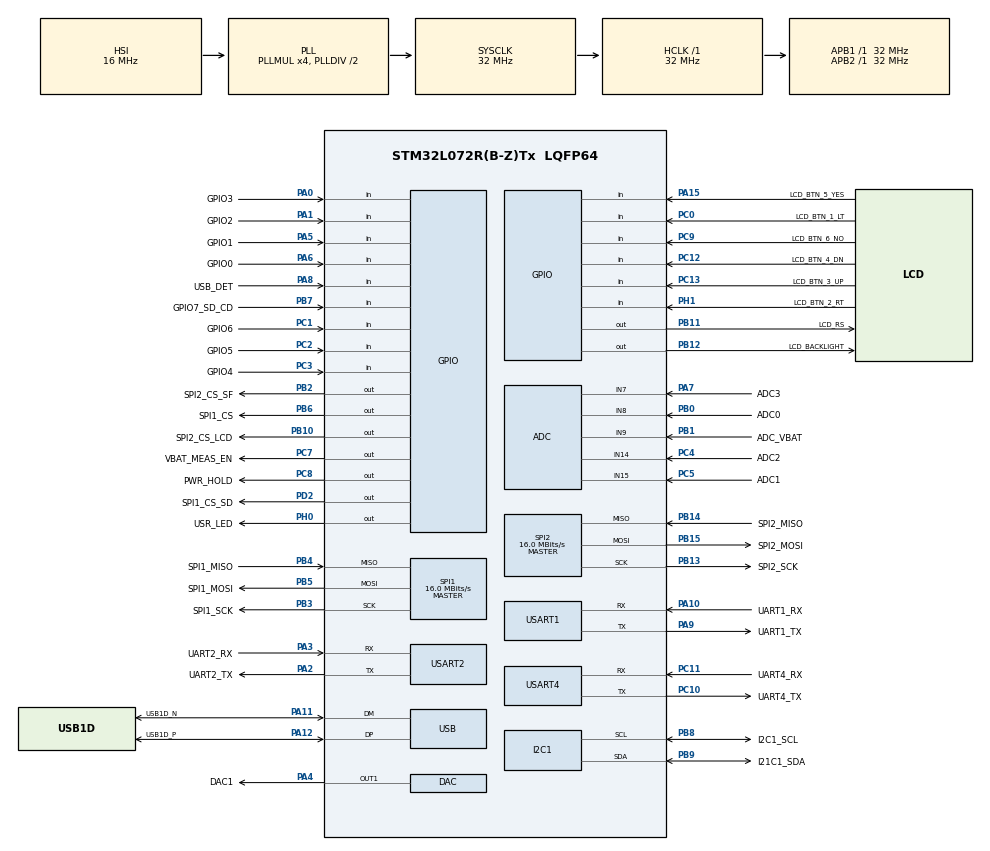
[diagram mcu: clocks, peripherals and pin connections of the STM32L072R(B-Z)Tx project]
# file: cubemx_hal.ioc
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PH0-OSC_IN.Signal=GPIO_Output
SPI1.VirtualType=VM_MASTER
SPI2.VirtualType=VM_MASTER
PA10.GPIO_PuPd=GPIO_PULLUP
PC12.Signal=GPIO_Input
PB14.GPIO_Label=SPI2_MISO
USART1.WordLength=WORDLENGTH_8B
PA14.GPIO_Label=SWCLK
PA3.GPIO_PuPd=GPIO_PULLUP
PC6.GPIO_Label=PWM_BUZZER
VP_RTC_VS_RTC_Activate.Mode=RTC_Enabled
PA6.GPIO_Label=GPIO0
PB6.GPIO_Label=SPI1_CS
PC5.Mode=IN15
PA3.GPIO_Speed=GPIO_SPEED_FREQ_LOW
PB13.Signal=SPI2_SCK
PC15-OSC32_OUT.GPIO_Label=OSC32_OUT
PB3.GPIO_Speed=GPIO_SPEED_FREQ_HIGH
RCC.SYSCLKSource=RCC_SYSCLKSOURCE_PLLCLK
PB11.GPIO_Speed=GPIO_SPEED_FREQ_HIGH
SPI1.Direction=SPI_DIRECTION_2LINES
RCC.APB2TimFreq_Value=32000000
PB6.Signal=GPIO_Output
PC7.Signal=GPIO_Output
PB12.PinState=GPIO_PIN_SET
SPI1.CalculateBaudRate=16.0 MBits/s
PC3.Signal=GPIO_Input
PA1.GPIO_PuPd=GPIO_PULLDOWN
PB2.Signal=GPIO_Output
PB3.Mode=Full_Duplex_Master
PC1.GPIO_PuPd=GPIO_PULLDOWN
RCC.RTCClockSelection=RCC_RTCCLKSOURCE_LSE
PB12.GPIO_Label=LCD_BACKLIGHT
PC4.GPIO_Label=ADC2
RCC.RTCClockSelectionVirtual=RCC_RTCCLKSOURCE_LSE
PB14.Mode=Full_Duplex_Master
PA5.GPIO_PuPd=GPIO_PULLDOWN
PB1.GPIO_Label=ADC_VBAT
SPI2.CalculateBaudRate=16.0 MBits/s
PC11.GPIO_Speed=GPIO_SPEED_FREQ_LOW
PA8.Signal=GPIO_Input
PA0.Signal=GPIO_Input
Mcu.Package=LQFP64
PB9.Signal=I2C1_SDA
PB1.Signal=ADC_IN9
PB14.GPIO_PuPd=GPIO_PULLDOWN
SPI2.Mode=SPI_MODE_MASTER
PA10.Signal=USART1_RX
VP_RTC_VS_RTC_Calendar.Mode=RTC_Calendar
PC11.Mode=Asynchronous
PB8.GPIO_PuPdOD=GPIO_PULLUP
PB5.GPIO_Speed=GPIO_SPEED_FREQ_HIGH
RCC.APB1TimFreq_Value=32000000
PB13.Mode=Full_Duplex_Master
PC12.GPIO_PuPd=GPIO_PULLUP
PA4.GPIO_Label=DAC1
PC4.Mode=IN14
RCC.HSI48_VALUE=48000000
PB7.GPIO_PuPd=GPIO_PULLUP
PA9.GPIO_Label=UART1_TX
PC13.Signal=GPIO_Input
PC6.Signal=S_TIM3_CH1
PC2.Signal=GPIO_Input
PB11.GPIO_Label=LCD_RS
PA11.GPIO_Label=USB1D_N
PC0.Signal=GPIO_Input
PC14-OSC32_IN.Signal=RCC_OSC32_IN
PA3.Mode=Asynchronous
RCC.HSI16_VALUE=16000000
PB8.GPIO_Label=I2C1_SCL
PA8.GPIO_Label=USB_DET
PB14.GPIO_Speed=GPIO_SPEED_FREQ_HIGH
USB_DEVICE.PRODUCT_STRING_CDC_FS=Hero Board
PA9.Signal=USART1_TX
I2C1.Timing=0x00707CBB
PB13.GPIO_Speed=GPIO_SPEED_FREQ_HIGH
PB4.GPIO_PuPd=GPIO_PULLUP
PH1-OSC_OUT.GPIO_PuPd=GPIO_PULLUP
PB10.Signal=GPIO_Output
PB14.Signal=SPI2_MISO
PA5.Signal=GPIO_Input
USART4.VirtualMode-Asynchronous=VM_ASYNC
PB4.GPIO_Label=SPI1_MISO
PB15.GPIO_Label=SPI2_MOSI
SPI1.Mode=SPI_MODE_MASTER
PA1.GPIO_Label=GPIO2
PC9.GPIO_PuPd=GPIO_PULLUP
PH1-OSC_OUT.GPIO_Label=LCD_BTN_2_RT
PA13.Mode=Serial_Wire
PC7.GPIO_Label=VBAT_MEAS_EN
PA4.Signal=COMP_DAC1_group
PB5.Signal=SPI1_MOSI
PA5.GPIO_Label=GPIO1
PC12.GPIO_Label=LCD_BTN_4_DN
PB6.PinState=GPIO_PIN_SET
PA11.Signal=USB_DM
ProjectManager.HeapSize=0x200
PB1.Mode=IN9
PB8.Mode=I2C
PC3.GPIO_Label=GPIO4
PD2.Signal=GPIO_Output
PB0.Signal=ADC_IN8
PC1.Signal=GPIO_Input
PD2.GPIO_Label=SPI1_CS_SD
Mcu.Family=STM32L0
PB10.PinState=GPIO_PIN_SET
USB_DEVICE.CLASS_NAME_FS=CDC
NVIC.USB_IRQn=true\:0\:0\:false\:false\:true\:false\:true
PC10.Signal=USART4_TX
PA0.GPIO_Label=GPIO3
PA2.GPIO_Speed=GPIO_SPEED_FREQ_LOW
PC0.GPIO_Label=LCD_BTN_1_LT
PA11.Mode=Device
PB0.GPIO_Label=ADC0
PC10.GPIO_Speed=GPIO_SPEED_FREQ_LOW
PC13.GPIO_Label=LCD_BTN_3_UP
PB13.GPIO_Label=SPI2_SCK
PB11.Signal=GPIO_Output
PB15.Signal=SPI2_MOSI
ProjectManager.StackSize=0x400
PC8.PinState=GPIO_PIN_SET
RCC.HSI48MClockSelection=RCC_USBCLKSOURCE_HSI48
USB_DEVICE.MANUFACTURER_STRING=PICONOMIX
PA15.GPIO_Label=LCD_BTN_5_YES
PC11.GPIO_PuPd=GPIO_PULLUP
PA12.Signal=USB_DP
RCC.HCLKFreq_Value=32000000
RCC.AHBFreq_Value=32000000
PH0-OSC_IN.GPIO_Label=USR_LED
RCC.HSE_VALUE=8000000
USART2.VirtualMode-Asynchronous=VM_ASYNC
RCC.PLLMUL=RCC_PLLMUL_4
PA6.GPIO_PuPd=GPIO_PULLDOWN
PB4.Mode=Full_Duplex_Master
PC14-OSC32_IN.Mode=LSE-External-Oscillator
PA14.Mode=Serial_Wire
PC11.GPIO_Label=UART4_RX
PB5.Mode=Full_Duplex_Master
PA10.GPIO_Label=UART1_RX
PC13.GPIO_PuPd=GPIO_PULLUP
PB7.Signal=GPIO_Input
SH.S_TIM3_CH1.0=TIM3_CH1
PB7.GPIO_Label=GPIO7_SD_CD
PA6.Signal=GPIO_Input
PA0.GPIO_PuPd=GPIO_PULLDOWN
PA2.GPIO_Label=UART2_TX
PA15.Signal=GPIO_Input
USART2.WordLength=WORDLENGTH_8B
PA10.GPIO_Speed=GPIO_SPEED_FREQ_LOW
PB9.GPIO_Speed=GPIO_SPEED_FREQ_LOW
PB5.GPIO_Label=SPI1_MOSI
PC14-OSC32_IN.GPIO_Label=OSC32_IN
SPI2.Direction=SPI_DIRECTION_2LINES
PC5.Signal=ADC_IN15
USART4.WordLength=WORDLENGTH_8B
PC0.GPIO_PuPd=GPIO_PULLUP
PC2.GPIO_Label=GPIO5
VP_TIM3_VS_ClockSourceINT.Mode=Internal
PB4.Signal=SPI1_MISO
PA3.Signal=USART2_RX
PB3.GPIO_Label=SPI1_SCK
RCC.MSI_VALUE=2097000
PC15-OSC32_OUT.Mode=LSE-External-Oscillator
SH.COMP_DAC1_group.0=DAC_OUT1,DAC_OUT1
PA7.Mode=IN7
PB9.GPIO_Label=I21C1_SDA
PC10.GPIO_Label=UART4_TX
PA10.Mode=Asynchronous
PC9.GPIO_Label=LCD_BTN_6_NO
USB_DEVICE.VirtualModeFS=Cdc_FS
PC11.Signal=USART4_RX
PC8.Signal=GPIO_Output
PC4.Signal=ADC_IN14
PC10.Mode=Asynchronous
PA12.GPIO_Label=USB1D_P
PC8.GPIO_Label=PWR_HOLD
USART1.VirtualMode-Asynchronous=VM_ASYNC
PA13.Signal=SYS_SWDIO
PA9.Mode=Asynchronous
ProjectManager.TargetToolchain=STM32CubeIDE
PB10.GPIO_Label=SPI2_CS_LCD
VP_USB_DEVICE_VS_USB_DEVICE_CDC_FS.Mode=CDC_FS
PB9.Mode=I2C
PC15-OSC32_OUT.Signal=RCC_OSC32_OUT
PA1.Signal=GPIO_Input
VP_FATFS_VS_Generic.Mode=User_defined
PD2.PinState=GPIO_PIN_SET
PB0.Mode=IN8
board=cubemx_hal
RCC.VCOOutputFreq_Value=64000000
PB15.Mode=Full_Duplex_Master
PB4.GPIO_Speed=GPIO_SPEED_FREQ_HIGH
RCC.APB2Freq_Value=32000000
PB15.GPIO_Speed=GPIO_SPEED_FREQ_HIGH
PC1.GPIO_Label=GPIO6
PH1-OSC_OUT.Signal=GPIO_Input
PC2.GPIO_PuPd=GPIO_PULLDOWN
Mcu.Name=STM32L072R(B-Z)Tx
PB2.PinState=GPIO_PIN_SET
PA2.Signal=USART2_TX
PA13.GPIO_Label=SWDIO
PB3.Signal=SPI1_SCK
RCC.SYSCLKFreq_VALUE=32000000
PA7.GPIO_Label=ADC3
PA12.Mode=Device
PC5.GPIO_Label=ADC1
PA14.Signal=SYS_SWCLK
PB2.GPIO_Label=SPI2_CS_SF
PB9.GPIO_PuPdOD=GPIO_PULLUP
RCC.HSI_VALUE=16000000
PA15.GPIO_PuPd=GPIO_PULLUP
PA2.Mode=Asynchronous
PA9.GPIO_Speed=GPIO_SPEED_FREQ_LOW
PB8.Signal=I2C1_SCL
PC9.Signal=GPIO_Input
RCC.APB1Freq_Value=32000000
PB8.GPIO_Speed=GPIO_SPEED_FREQ_LOW
USB_DEVICE.VirtualMode=Cdc
PB12.Signal=GPIO_Output
PC3.GPIO_PuPd=GPIO_PULLDOWN
PA3.GPIO_Label=UART2_RX
PA7.Signal=ADC_IN7

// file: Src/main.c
/* USER CODE BEGIN Header */
/**
  ******************************************************************************
  * @file           : main.c
  * @brief          : Main program body
  ******************************************************************************
  * @attention
  *
  * <h2><center>&copy; Copyright (c) 2019 STMicroelectronics.
  * All rights reserved.</center></h2>
  *
  * This software component is licensed by ST under Ultimate Liberty license
  * SLA0044, the "License"; You may not use this file except in compliance with
  * the License. You may obtain a copy of the License at:
  *                             www.st.com/SLA0044
  *
  ******************************************************************************
  */
/* USER CODE END Header */

#include "main.h"
#include "adc.h"
#include "dac.h"
#include "fatfs.h"
#include "i2c.h"
#include "rtc.h"
#include "spi.h"
#include "tim.h"
#include "usart.h"
#include "usb_device.h"
#include "gpio.h"

void SystemClock_Config(void);

int main(void)
{

  /* MCU Configuration--------------------------------------------------------*/

  /* Reset of all peripherals, Initializes the Flash interface and the Systick. */
  HAL_Init();

  /* Configure the system clock */
  SystemClock_Config();

  /* Initialize all configured peripherals */
  MX_GPIO_Init();
  MX_ADC_Init();
  MX_DAC_Init();
  MX_I2C1_Init();
  MX_RTC_Init();
  MX_SPI1_Init();
  MX_SPI2_Init();
  MX_USART1_UART_Init();
  MX_USART2_UART_Init();
  MX_USART4_UART_Init();
  MX_USB_DEVICE_Init();
  MX_FATFS_Init();
  MX_TIM3_Init();

  /* Infinite loop */
  while (1)
  {

    /* USER CODE BEGIN 3 */
      // Button being pressed?
      if(HAL_GPIO_ReadPin(LCD_BTN_5_YES_GPIO_Port, LCD_BTN_5_YES_Pin) == GPIO_PIN_RESET)
      {
          // Disable LED
          HAL_GPIO_WritePin(USR_LED_GPIO_Port, USR_LED_Pin, GPIO_PIN_RESET);
      }
      else
      {
          // Enable LED
          HAL_GPIO_WritePin(USR_LED_GPIO_Port, USR_LED_Pin, GPIO_PIN_SET);
      }
  }
  /* USER CODE END 3 */
}

void SystemClock_Config(void)
{
  RCC_OscInitTypeDef RCC_OscInitStruct = {0};
  RCC_ClkInitTypeDef RCC_ClkInitStruct = {0};
  RCC_PeriphCLKInitTypeDef PeriphClkInit = {0};

  /** Configure the main internal regulator output voltage
  */
  __HAL_PWR_VOLTAGESCALING_CONFIG(PWR_REGULATOR_VOLTAGE_SCALE1);
  /** Configure LSE Drive Capability
  */
  HAL_PWR_EnableBkUpAccess();
  __HAL_RCC_LSEDRIVE_CONFIG(RCC_LSEDRIVE_LOW);
  /** Initializes the CPU, AHB and APB busses clocks
  */
  RCC_OscInitStruct.OscillatorType = RCC_OSCILLATORTYPE_HSI|RCC_OSCILLATORTYPE_LSE
                              |RCC_OSCILLATORTYPE_HSI48;
  RCC_OscInitStruct.LSEState = RCC_LSE_ON;
  RCC_OscInitStruct.HSIState = RCC_HSI_ON;
  RCC_OscInitStruct.HSICalibrationValue = RCC_HSICALIBRATION_DEFAULT;
  RCC_OscInitStruct.HSI48State = RCC_HSI48_ON;
  RCC_OscInitStruct.PLL.PLLState = RCC_PLL_ON;
  RCC_OscInitStruct.PLL.PLLSource = RCC_PLLSOURCE_HSI;
  RCC_OscInitStruct.PLL.PLLMUL = RCC_PLLMUL_4;
  RCC_OscInitStruct.PLL.PLLDIV = RCC_PLLDIV_2;
  if (HAL_RCC_OscConfig(&RCC_OscInitStruct) != HAL_OK)
  {
    Error_Handler();
  }
  /** Initializes the CPU, AHB and APB busses clocks
  */
  RCC_ClkInitStruct.ClockType = RCC_CLOCKTYPE_HCLK|RCC_CLOCKTYPE_SYSCLK
                              |RCC_CLOCKTYPE_PCLK1|RCC_CLOCKTYPE_PCLK2;
  RCC_ClkInitStruct.SYSCLKSource = RCC_SYSCLKSOURCE_PLLCLK;
  RCC_ClkInitStruct.AHBCLKDivider = RCC_SYSCLK_DIV1;
  RCC_ClkInitStruct.APB1CLKDivider = RCC_HCLK_DIV1;
  RCC_ClkInitStruct.APB2CLKDivider = RCC_HCLK_DIV1;

  if (HAL_RCC_ClockConfig(&RCC_ClkInitStruct, FLASH_LATENCY_1) != HAL_OK)
  {
    Error_Handler();
  }
  PeriphClkInit.PeriphClockSelection = RCC_PERIPHCLK_USART1|RCC_PERIPHCLK_USART2
                              |RCC_PERIPHCLK_I2C1|RCC_PERIPHCLK_RTC
                              |RCC_PERIPHCLK_USB;
  PeriphClkInit.Usart1ClockSelection = RCC_USART1CLKSOURCE_PCLK2;
  PeriphClkInit.Usart2ClockSelection = RCC_USART2CLKSOURCE_PCLK1;
  PeriphClkInit.I2c1ClockSelection = RCC_I2C1CLKSOURCE_PCLK1;
  PeriphClkInit.RTCClockSelection = RCC_RTCCLKSOURCE_LSE;
  PeriphClkInit.UsbClockSelection = RCC_USBCLKSOURCE_HSI48;
  if (HAL_RCCEx_PeriphCLKConfig(&PeriphClkInit) != HAL_OK)
  {
    Error_Handler();
  }
}

void Error_Handler(void)
{
}

/************************ (C) COPYRIGHT STMicroelectronics *****END OF FILE****/
